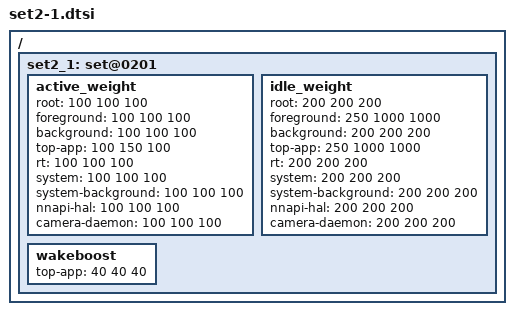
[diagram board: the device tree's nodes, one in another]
/ {
	/* performance mode - touch boost */
	set2_1: set@0201 {
		/* weight (%) applied to active cpu's efficiency */
		active_weight {	   		/* LIT MED BIG */
			root            	= <100 100 100>;
			foreground      	= <100 100 100>;
			background      	= <100 100 100>;
			top-app         	= <100 150 100>;
			rt			= <100 100 100>;
			system			= <100 100 100>;
			system-background	= <100 100 100>;
			nnapi-hal		= <100 100 100>;
			camera-daemon		= <100 100 100>;
		};

		/* weight (%) applied to idle cpu's efficiency */
		idle_weight {	   		/* LIT  MED  BIG */
			root            	= <200  200  200>;
			foreground      	= <250 1000 1000>;
			background      	= <200  200  200>;
			top-app         	= <250 1000 1000>;
			rt			= <200  200  200>;
			system			= <200  200  200>;
			system-background	= <200  200  200>;
			nnapi-hal		= <200  200  200>;
			camera-daemon		= <200  200  200>;
		};

		/* Boosting margin for waking up task */
		wakeboost {			/* LIT MED BIG */
			top-app			= < 40  40  40>;
		};
	};
};
